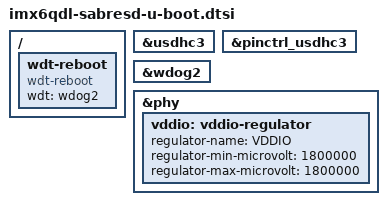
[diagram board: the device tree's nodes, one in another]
// SPDX-License-Identifier: GPL-2.0+
/*
 * Copyright (C) 2019 NXP
 */

#include "imx6qdl-u-boot.dtsi"

/ {
	wdt-reboot {
		compatible = "wdt-reboot";
		wdt = <&wdog2>;
		bootph-pre-ram;
	};
};

&usdhc3 {
	bootph-pre-ram;
};

&pinctrl_usdhc3 {
	bootph-pre-ram;
};

&wdog2 {
	bootph-pre-ram;
};

&phy {
	vddio: vddio-regulator {
		regulator-name = "VDDIO";
		regulator-min-microvolt = <1800000>;
		regulator-max-microvolt = <1800000>;
	};
};
